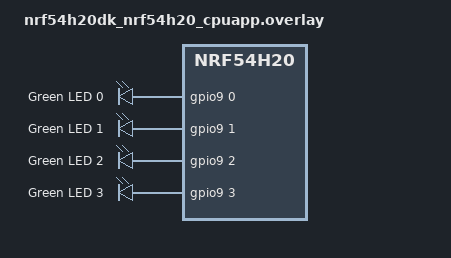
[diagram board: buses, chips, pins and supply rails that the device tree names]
/*
 * Copyright (c) 2024 Nordic Semiconductor ASA
 *
 * SPDX-License-Identifier: LicenseRef-Nordic-5-Clause
 */

 /{
	/delete-node/ leds;

	leds0 {
		compatible = "gpio-leds";
		led0: led_0 {
			gpios = <&gpio9 0 GPIO_ACTIVE_HIGH>;
			label = "Green LED 0";
		};
	};

	leds1 {
		compatible = "gpio-leds";
		led1: led_1 {
			gpios = <&gpio9 1 GPIO_ACTIVE_HIGH>;
			label = "Green LED 1";
		};
	};

	leds2 {
		compatible = "gpio-leds";
		led2: led_2 {
			gpios = <&gpio9 2 GPIO_ACTIVE_HIGH>;
			label = "Green LED 2";
		};
	};

	leds3 {
		compatible = "gpio-leds";
		led3: led_3 {
			gpios = <&gpio9 3 GPIO_ACTIVE_HIGH>;
			label = "Green LED 3";
		};
	};
};
